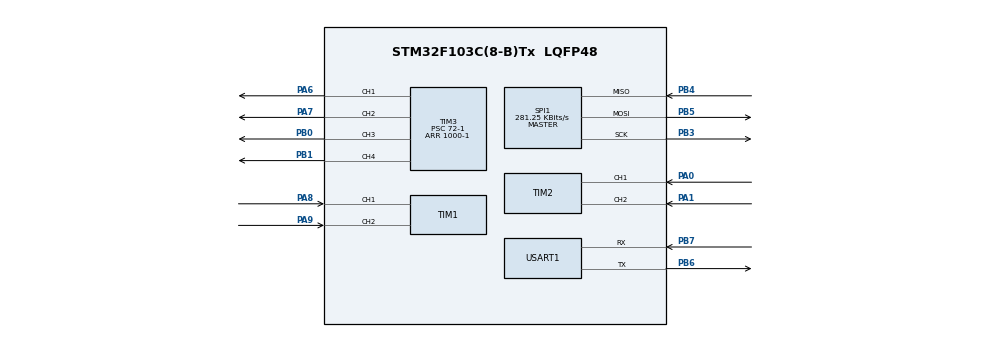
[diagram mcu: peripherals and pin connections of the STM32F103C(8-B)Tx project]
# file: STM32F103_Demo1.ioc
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Mcu.Family=STM32F1
Mcu.Name=STM32F103C(8-B)Tx
Mcu.Package=LQFP48
NVIC.PriorityGroup=NVIC_PRIORITYGROUP_4
NVIC.TIM2_IRQn=true\:0\:0\:false\:false\:true\:true\:true\:true
NVIC.TIM4_IRQn=true\:0\:0\:false\:false\:true\:true\:true\:true
NVIC.USART1_IRQn=true\:0\:0\:false\:false\:true\:true\:true\:true
PA0-WKUP.Signal=S_TIM2_CH1_ETR
PA1.Signal=S_TIM2_CH2
PA13.Mode=Serial_Wire
PA13.Signal=SYS_JTMS-SWDIO
PA14.Mode=Serial_Wire
PA14.Signal=SYS_JTCK-SWCLK
PA6.Signal=S_TIM3_CH1
PA7.Signal=S_TIM3_CH2
PA8.Signal=S_TIM1_CH1
PA9.Signal=S_TIM1_CH2
PB0.Signal=S_TIM3_CH3
PB1.Signal=S_TIM3_CH4
PB3.Mode=Full_Duplex_Master
PB3.Signal=SPI1_SCK
PB4.Mode=Full_Duplex_Master
PB4.Signal=SPI1_MISO
PB5.Mode=Full_Duplex_Master
PB5.Signal=SPI1_MOSI
PB6.Mode=Asynchronous
PB6.Signal=USART1_TX
PB7.Mode=Asynchronous
PB7.Signal=USART1_RX
PD0-OSC_IN.Mode=HSE-External-Oscillator
PD0-OSC_IN.Signal=RCC_OSC_IN
PD1-OSC_OUT.Mode=HSE-External-Oscillator
PD1-OSC_OUT.Signal=RCC_OSC_OUT
ProjectManager.HeapSize=0x200
ProjectManager.StackSize=0x400
ProjectManager.TargetToolchain=STM32CubeIDE
RCC.AHBFreq_Value=72000000
RCC.APB1CLKDivider=RCC_HCLK_DIV2
RCC.APB1Freq_Value=36000000
RCC.APB1TimFreq_Value=72000000
RCC.APB2Freq_Value=72000000
RCC.APB2TimFreq_Value=72000000
RCC.HCLKFreq_Value=72000000
RCC.PLLMUL=RCC_PLL_MUL9
RCC.PLLSourceVirtual=RCC_PLLSOURCE_HSE
RCC.SYSCLKFreq_VALUE=72000000
RCC.SYSCLKSource=RCC_SYSCLKSOURCE_PLLCLK
RCC.USBFreq_Value=72000000
SH.S_TIM1_CH1.0=TIM1_CH1,Encoder_Interface
SH.S_TIM1_CH2.0=TIM1_CH2,Encoder_Interface
SH.S_TIM2_CH1_ETR.0=TIM2_CH1,Encoder_Interface
SH.S_TIM2_CH2.0=TIM2_CH2,Encoder_Interface
SH.S_TIM3_CH1.0=TIM3_CH1,PWM Generation1 CH1
SH.S_TIM3_CH2.0=TIM3_CH2,PWM Generation2 CH2
SH.S_TIM3_CH3.0=TIM3_CH3,PWM Generation3 CH3
SH.S_TIM3_CH4.0=TIM3_CH4,PWM Generation4 CH4
SPI1.BaudRatePrescaler=SPI_BAUDRATEPRESCALER_256
SPI1.CLKPolarity=SPI_POLARITY_HIGH
SPI1.CalculateBaudRate=281.25 KBits/s
SPI1.Direction=SPI_DIRECTION_2LINES
SPI1.FirstBit=SPI_FIRSTBIT_LSB
SPI1.Mode=SPI_MODE_MASTER
SPI1.VirtualType=VM_MASTER
TIM1.AutoReloadPreload=TIM_AUTORELOAD_PRELOAD_ENABLE
TIM1.EncoderMode=TIM_ENCODERMODE_TI12
TIM2.AutoReloadPreload=TIM_AUTORELOAD_PRELOAD_ENABLE
TIM2.EncoderMode=TIM_ENCODERMODE_TI12
TIM3.AutoReloadPreload=TIM_AUTORELOAD_PRELOAD_ENABLE
TIM3.Channel-PWM\ Generation1\ CH1=TIM_CHANNEL_1
TIM3.Channel-PWM\ Generation2\ CH2=TIM_CHANNEL_2
TIM3.Channel-PWM\ Generation3\ CH3=TIM_CHANNEL_3
TIM3.Channel-PWM\ Generation4\ CH4=TIM_CHANNEL_4
TIM3.Period=1000-1
TIM3.Prescaler=72-1
TIM4.AutoReloadPreload=TIM_AUTORELOAD_PRELOAD_ENABLE
TIM4.Period=10000-1
TIM4.Prescaler=720-1
USART1.VirtualMode=VM_ASYNC
VP_TIM3_VS_ClockSourceINT.Mode=Internal
VP_TIM4_VS_ClockSourceINT.Mode=Internal
board=custom

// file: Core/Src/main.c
/* USER CODE BEGIN Header */
/**
  ******************************************************************************
  * @file           : main.c
  * @brief          : Main program body
  ******************************************************************************
  * @attention
  *
  * Copyright (c) 2023 STMicroelectronics.
  * All rights reserved.
  *
  * This software is licensed under terms that can be found in the LICENSE file
  * in the root directory of this software component.
  * If no LICENSE file comes with this software, it is provided AS-IS.
  *
  ******************************************************************************
  */
/* USER CODE END Header */
#include "main.h"
#include "spi.h"
#include "tim.h"
#include "usart.h"
#include "gpio.h"

/* USER CODE BEGIN Includes */
#include "motor_control.h"
#include "bsp_GPIO_ENABLE.h"
#include "retarget.h"
#include "bsp_spi.h"

/* USER CODE END Includes */

void SystemClock_Config(void);

int main(void)
{

  /* MCU Configuration--------------------------------------------------------*/

  /* Reset of all peripherals, Initializes the Flash interface and the Systick. */
  HAL_Init();

  /* Configure the system clock */
  SystemClock_Config();

  /* Initialize all configured peripherals */
  MX_GPIO_Init();
  MX_TIM4_Init();
  MX_USART1_UART_Init();
  MX_TIM1_Init();
  MX_TIM2_Init();
  MX_TIM3_Init();
  MX_SPI1_Init();
  /* USER CODE BEGIN 2 */
    MY_GPIO_Init();
    RetargetInit(&huart1);
    /*
    HAL_GPIO_WritePin(GPIOC,GPIO_PIN_13,GPIO_PIN_RESET);
    HAL_GPIO_WritePin(GPIOB,GPIO_PIN_3,GPIO_PIN_RESET);
    HAL_GPIO_WritePin(GPIOB,GPIO_PIN_4,GPIO_PIN_SET);
    HAL_TIM_PWM_Start(&htim3,TIM_CHANNEL_1);
    __HAL_TIM_SET_COMPARE(&htim4,TIM_CHANNEL_1,1000);
*/

    motor_init(0,htim2,TIM_CHANNEL_1);
    motor_start(0,htim3,TIM_CHANNEL_1);
    HAL_TIM_Base_Start_IT(&htim4);
    //PS2data[9] = {0x00,0x00,0x00,0x00,0x00,0x00,0x00,0x00,0x00};
/*
    HAL_TIM_Encoder_Start_IT(&htim2,TIM_CHANNEL_ALL);
    motor_start(1,htim3,TIM_CHANNEL_2);
*/
/*
    PS2_Get();
    set_pid_target(&motor[0].motor_pid,(float)(PS2data[8]-127)/127.0*1000.0);
    printf("%d,%d,%d,%d,%d,%d,%d,%d,%d\n",PS2data[0],PS2data[1],PS2data[2],PS2data[3],PS2data[4],PS2data[5],PS2data[6],PS2data[7],PS2data[8]);
*/
  /* USER CODE END 2 */

  /* Infinite loop */
  while (1)
  {
      PS2_Get();
      set_pid_target(&motor[0].motor_pid,(float)(PS2data[8]-127)/127.0*1000.0);
      printf("%d,%d,%d,%d,%d,%d,%d,%d,%d,%f\n",PS2data[0],PS2data[1],PS2data[2],PS2data[3],PS2data[4],PS2data[5],PS2data[6],PS2data[7],PS2data[8],motor[0].actual_speed);

  }
}

void SystemClock_Config(void)

/*
 * include_directories(Core/Inc Drivers/STM32F1xx_HAL_Driver/Inc Drivers/STM32F1xx_HAL_Driver/Inc/Legacy Drivers/CMSIS/Device/ST/STM32F1xx/Include Drivers/CMSIS/Include driver/Include eMPL-hal mllite mpl)

add_definitions(-DDEBUG -DUSE_HAL_DRIVER -DSTM32F103xB)

file(GLOB_RECURSE SOURCES "Core/*.*" "Drivers/*.*" "mpl/*.*" "mllite/*.*" "eMPL-hal/*.*" "driver/eMPL/*.*")
*/

 */

{
  RCC_OscInitTypeDef RCC_OscInitStruct = {0};
  RCC_ClkInitTypeDef RCC_ClkInitStruct = {0};

  /** Initializes the RCC Oscillators according to the specified parameters
  * in the RCC_OscInitTypeDef structure.
  */
  RCC_OscInitStruct.OscillatorType = RCC_OSCILLATORTYPE_HSE;
  RCC_OscInitStruct.HSEState = RCC_HSE_ON;
  RCC_OscInitStruct.HSEPredivValue = RCC_HSE_PREDIV_DIV1;
  RCC_OscInitStruct.HSIState = RCC_HSI_ON;
  RCC_OscInitStruct.PLL.PLLState = RCC_PLL_ON;
  RCC_OscInitStruct.PLL.PLLSource = RCC_PLLSOURCE_HSE;
  RCC_OscInitStruct.PLL.PLLMUL = RCC_PLL_MUL9;
  if (HAL_RCC_OscConfig(&RCC_OscInitStruct) != HAL_OK)
  {
    Error_Handler();
  }

  /** Initializes the CPU, AHB and APB buses clocks
  */
  RCC_ClkInitStruct.ClockType = RCC_CLOCKTYPE_HCLK|RCC_CLOCKTYPE_SYSCLK
                              |RCC_CLOCKTYPE_PCLK1|RCC_CLOCKTYPE_PCLK2;
  RCC_ClkInitStruct.SYSCLKSource = RCC_SYSCLKSOURCE_PLLCLK;
  RCC_ClkInitStruct.AHBCLKDivider = RCC_SYSCLK_DIV1;
  RCC_ClkInitStruct.APB1CLKDivider = RCC_HCLK_DIV2;
  RCC_ClkInitStruct.APB2CLKDivider = RCC_HCLK_DIV1;

  if (HAL_RCC_ClockConfig(&RCC_ClkInitStruct, FLASH_LATENCY_2) != HAL_OK)
  {
    Error_Handler();
  }
}

void Error_Handler(void)
{
  __disable_irq();
  while (1)
  {
  }
}
